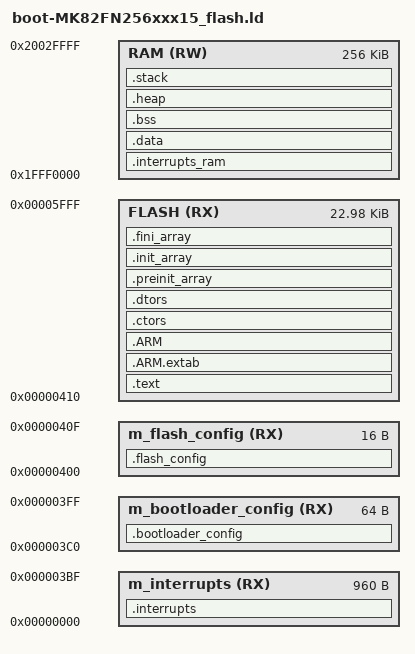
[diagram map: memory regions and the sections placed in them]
/*
** ###################################################################
**     Processors:          MK82FN256CAx15
**                          MK82FN256VDC15
**                          MK82FN256VLL15
**                          MK82FN256VLQ15
**
**     Compiler:            GNU C Compiler
**     Reference manual:    K82P121M150SF5RM, Rev. 0, May 2015
**     Version:             rev. 1.2, 2015-07-29
**     Build:               b190916
**
**     Abstract:
**         Linker file for the GNU C Compiler
**
**     Copyright 2016 Freescale Semiconductor, Inc.
**     Copyright 2016-2019 NXP
**     All rights reserved.
**
**     SPDX-License-Identifier: BSD-3-Clause
**
**     http:                 www.nxp.com
**     mail:                 support@nxp.com
**
** ###################################################################
*/

/* Entry Point */
ENTRY(Reset_Handler)

HEAP_SIZE  = DEFINED(__heap_size__)  ? __heap_size__  : 0x10000;
STACK_SIZE = DEFINED(__stack_size__) ? __stack_size__ : 0x0400;
M_VECTOR_RAM_SIZE = DEFINED(__ram_vector_table__) ? 0x0400 : 0x0;
IMGHDR_SIZE = DEFINED(_imghdr_size) ? _imghdr_size : 0x0;

/* Specify the memory areas */
MEMORY
{
  m_interrupts          (RX)  : ORIGIN = 0x00000000, LENGTH = 0x000003C0
  m_bootloader_config   (RX)  : ORIGIN = 0x000003C0, LENGTH = 0x00000040
  m_flash_config        (RX)  : ORIGIN = 0x00000400, LENGTH = 0x00000010
  FLASH                 (RX)  : ORIGIN = 0x00000410, LENGTH = 0x00006000 - 0x410
  RAM                   (RW)  : ORIGIN = 0x1FFF0000, LENGTH = 0x00040000
}

/* Define output sections */
SECTIONS
{
  /* The startup code goes first into internal flash */
  .interrupts :
  {
    __VECTOR_TABLE = .;
    . = ALIGN(4);
    KEEP(*(.isr_vector))     /* Startup code */
    . = ALIGN(4);
  } > m_interrupts

  .bootloader_config :
  {
    . = ALIGN(4);
    KEEP(*(.BootloaderConfig)) /* Bootloader Configuration Area (BCA) */
    . = ALIGN(4);
  } > m_bootloader_config

  .flash_config :
  {
    . = ALIGN(4);
    KEEP(*(.FlashConfig))    /* Flash Configuration Field (FCF) */
    . = ALIGN(4);
  } > m_flash_config

  __text = .;    /* define a global symbol for start of the code */
  /* The program code and other data goes into internal flash */
  .text :
  {
    . = ALIGN(4);
    *(.text)                 /* .text sections (code) */
    *(.text*)                /* .text* sections (code) */
    *(.rodata)               /* .rodata sections (constants, strings, etc.) */
    *(.rodata*)              /* .rodata* sections (constants, strings, etc.) */
    *(.glue_7)               /* glue arm to thumb code */
    *(.glue_7t)              /* glue thumb to arm code */
    *(.eh_frame)
    KEEP (*(.init))
    KEEP (*(.fini))
    . = ALIGN(4);
    PROVIDE(mynewt_main = main);
  } > FLASH

  .ARM.extab :
  {
    *(.ARM.extab* .gnu.linkonce.armextab.*)
  } > FLASH

  .ARM :
  {
    __exidx_start = .;
    *(.ARM.exidx*)
    __exidx_end = .;
  } > FLASH

 .ctors :
  {
    __CTOR_LIST__ = .;
    /* gcc uses crtbegin.o to find the start of
       the constructors, so we make sure it is
       first.  Because this is a wildcard, it
       doesn't matter if the user does not
       actually link against crtbegin.o; the
       linker won't look for a file to match a
       wildcard.  The wildcard also means that it
       doesn't matter which directory crtbegin.o
       is in.  */
    KEEP (*crtbegin.o(.ctors))
    KEEP (*crtbegin?.o(.ctors))
    /* We don't want to include the .ctor section from
       from the crtend.o file until after the sorted ctors.
       The .ctor section from the crtend file contains the
       end of ctors marker and it must be last */
    KEEP (*(EXCLUDE_FILE(*crtend?.o *crtend.o) .ctors))
    KEEP (*(SORT(.ctors.*)))
    KEEP (*(.ctors))
    __CTOR_END__ = .;
  } > FLASH

  .dtors :
  {
    __DTOR_LIST__ = .;
    KEEP (*crtbegin.o(.dtors))
    KEEP (*crtbegin?.o(.dtors))
    KEEP (*(EXCLUDE_FILE(*crtend?.o *crtend.o) .dtors))
    KEEP (*(SORT(.dtors.*)))
    KEEP (*(.dtors))
    __DTOR_END__ = .;
  } > FLASH

  .preinit_array :
  {
    PROVIDE_HIDDEN (__preinit_array_start = .);
    KEEP (*(.preinit_array*))
    PROVIDE_HIDDEN (__preinit_array_end = .);
  } > FLASH

  .init_array :
  {
    PROVIDE_HIDDEN (__init_array_start = .);
    KEEP (*(SORT(.init_array.*)))
    KEEP (*(.init_array*))
    PROVIDE_HIDDEN (__init_array_end = .);
  } > FLASH

  .fini_array :
  {
    PROVIDE_HIDDEN (__fini_array_start = .);
    KEEP (*(SORT(.fini_array.*)))
    KEEP (*(.fini_array*))
    PROVIDE_HIDDEN (__fini_array_end = .);
  } > FLASH

  __etext = .;    /* define a global symbol at end of code */
  __DATA_ROM = .; /* Symbol is used by startup for data initialization */

  .interrupts_ram :
  {
    . = ALIGN(4);
    __VECTOR_RAM__ = .;
    __interrupts_ram_start__ = .; /* Create a global symbol at data start */
    *(.m_interrupts_ram)     /* This is a user defined section */
    . += M_VECTOR_RAM_SIZE;
    . = ALIGN(4);
    __interrupts_ram_end__ = .; /* Define a global symbol at data end */
  } > RAM
  __vector_tbl_reloc__ = __interrupts_ram_start__;
  __VECTOR_RAM = DEFINED(__ram_vector_table__) ? __VECTOR_RAM__ : ORIGIN(m_interrupts);
  __RAM_VECTOR_TABLE_SIZE_BYTES = DEFINED(__ram_vector_table__) ? (__interrupts_ram_end__ - __interrupts_ram_start__) : 0x0;

  .data : AT(__DATA_ROM)
  {
    . = ALIGN(4);
    __DATA_RAM = .;
    __data_start__ = .;      /* create a global symbol at data start */
    *(.data)                 /* .data sections */
    *(.data*)                /* .data* sections */
    KEEP(*(.jcr*))
    . = ALIGN(4);
    __data_end__ = .;        /* define a global symbol at data end */
  } > RAM

  __DATA_END = __DATA_ROM + (__data_end__ - __data_start__);
  text_end = ORIGIN(FLASH) + LENGTH(FLASH);
  ASSERT(__DATA_END <= text_end, "region m_text overflowed with text and data")

  /* Uninitialized data section */
  .bss :
  {
    /* This is used by the startup in order to initialize the .bss section */
    . = ALIGN(4);
    __START_BSS = .;
    __bss_start__ = .;
    *(.bss)
    *(.bss*)
    *(COMMON)
    . = ALIGN(4);
    __bss_end__ = .;
    __END_BSS = .;
  } > RAM

  .heap :
  {
    . = ALIGN(8);
    __end__ = .;
    PROVIDE(end = .);
    . = ALIGN(8);
    __HeapBase = .;
    . += HEAP_SIZE;
    __HeapLimit = .;
    __heap_limit = .; /* Add for _sbrk */
  } > RAM

  .stack :
  {
    . = ALIGN(8);
    . += STACK_SIZE;
  } > RAM

  /* Initializes stack on the end of block */
  __StackTop   = ORIGIN(RAM) + LENGTH(RAM);
  __StackLimit = __StackTop - STACK_SIZE;
  PROVIDE(__stack = __StackTop);

  .ARM.attributes 0 : { *(.ARM.attributes) }

  ASSERT(__StackLimit >= __HeapLimit, "region RAM overflowed")
}

  
